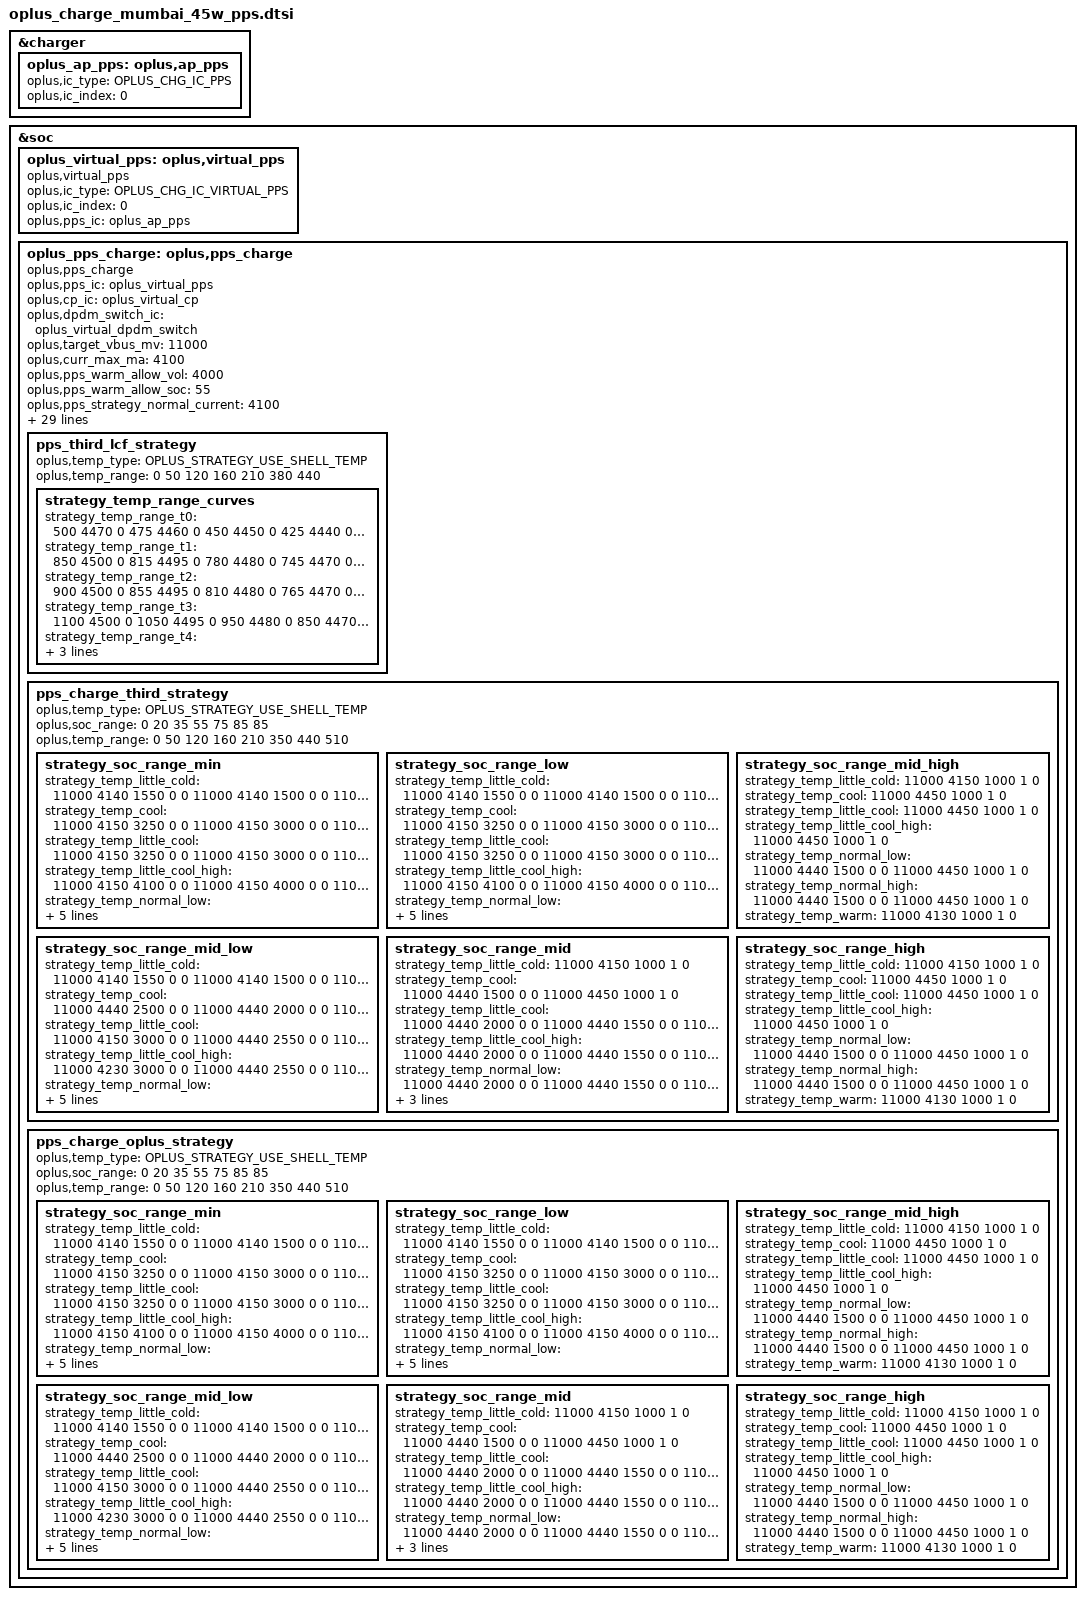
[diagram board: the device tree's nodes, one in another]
//ifdef OPLUS_FEATURE_CHG_BASIC

&charger {
	oplus_ap_pps: oplus,ap_pps {
		oplus,ic_type = <OPLUS_CHG_IC_PPS>;
		oplus,ic_index = <0>;
	};
};

&soc {
	oplus_virtual_pps: oplus,virtual_pps {
		compatible = "oplus,virtual_pps";

		oplus,ic_type = <OPLUS_CHG_IC_VIRTUAL_PPS>;
		oplus,ic_index = <0>;
		oplus,pps_ic = <&oplus_ap_pps>;
	};
	oplus_pps_charge: oplus,pps_charge {
		compatible = "oplus,pps_charge";
		oplus,pps_ic = <&oplus_virtual_pps>;
		oplus,cp_ic = <&oplus_virtual_cp>;
		oplus,dpdm_switch_ic = <&oplus_virtual_dpdm_switch>;

		// oplus,impedance_unit = <&oplus_pps_impedance_unit>;

		oplus,target_vbus_mv = <11000>;
		oplus,curr_max_ma = <4100>;

		oplus,pps_warm_allow_vol = <4000>;
		oplus,pps_warm_allow_soc = <55>;
		oplus,pps_strategy_normal_current = <4100>;
		oplus,pps_over_high_or_low_current = <4100>;
		oplus,pps_timeout_third = <17562>;
		oplus,pps_timeout_oplus = <17562>;
		oplus,pps_ibat_over_third = <9600>;
		oplus,pps_ibat_over_oplus = <9600>;
		oplus,pps_full_cool_sw_vbat = <4450>;
		oplus,pps_full_normal_sw_vbat = <4450>;
		oplus,pps_full_normal_hw_vbat = <4460>;
		oplus,pps_full_ffc_vbat = <4485>;
		oplus,pps_full_warm_vbat = <4130>;
		oplus,pps_full_cool_sw_vbat_third = <4450>;
		oplus,pps_full_normal_sw_vbat_third= <4450>;
		oplus,pps_full_normal_hw_vbat_third = <4460>;
		oplus,pps_current_change_timeout = <100>;
        // V1
		// oplus,pps_r_default = <270 45 10 45 20 20 20>;
		// oplus,pps_rmos_mohm = <5>;
		// oplus,pps_r_limit = <150 100 80 70 30>;
		oplus,pps_little_cool_high_temp = <210>;
		oplus,curve_strategy_name = "pps_ufcs_curve_v2";
		oplus,pps_strategy_batt_high_temp = <400 420 430
                                             400 410 420>;
		oplus,pps_strategy_high_current = <3000 2000 2000
                                           3000 3000 2000>;
		oplus,pps_charge_strategy_soc = <0 20 35 55 75 85 90>;
		oplus,pps_charge_strategy_temp = <0 50 120 160 350 440 510>;
		oplus,pps_low_curr_full_strategy_temp = <0 200 350 440>;
		oplus,pps_low_temp = <50>;

 		oplus,plc_strategy-data = <&pps_simple_strategy>;
 		oplus,plc_strategy-names = "default";
		pps_third_lcf_strategy {
			oplus,temp_type = <OPLUS_STRATEGY_USE_SHELL_TEMP>;
			oplus,temp_range = <0 50 120 160 210 380 440>;

			strategy_temp_range_curves {
				strategy_temp_range_t0 = <500 4470 0
								 475 4460 0
								 450 4450 0
								 425 4440 0
								 400 4430 1>;
				strategy_temp_range_t1 = <850 4500 0
								 815 4495 0
								 780 4480 0
								 745 4470 0
								 710 4460 1>;
				strategy_temp_range_t2 = <900 4500 0
								 855 4495 0
								 810 4480 0
								 765 4470 0
								 720 4460 1>;
				strategy_temp_range_t3 = <1100 4500 0
								 1050 4495 0
								 950 4480 0
								 850 4470 0
								 700 4460 1>;
				strategy_temp_range_t4 = <1150 4500 0
								 1100 4495 0
								 1000 4480 0
								 900 4470 0
								 750 4460 1>;
				strategy_temp_range_t5 = <1150 4500 0
								 1100 4495 0
								 1000 4480 0
								 900 4470 0
								 750 4460 1>;
			};
		};

		pps_charge_third_strategy {
			oplus,temp_type = <OPLUS_STRATEGY_USE_SHELL_TEMP>;
			oplus,soc_range = <0 20 35 55 75 85 85>;
			oplus,temp_range = <0 50 120 160 210 350 440 510>;

			strategy_soc_range_min {	//0-20
				strategy_temp_little_cold =	<11000 4140 1550 0 0
								11000 4140 1500 0 0
								11000 4150 1000 1 0>;
				strategy_temp_cool = <11000 4150 3250 0 0
								11000 4150 3000 0 0
								11000 4440 2550 0 0
								11000 4440 2500 0 0
								11000 4440 2000 0 0
								11000 4440 1550 0 0
								11000 4440 1500 0 0
								11000 4450 1000 1 0>;
				strategy_temp_little_cool =	<11000 4150 3250 0 0
								11000 4150 3000 0 0
								11000 4440 2550 0 0
								11000 4440 2500 0 0
								11000 4440 2000 0 0
								11000 4440 1550 0 0
								11000 4440 1500 0 0
								11000 4450 1000 1 0>;
				strategy_temp_little_cool_high = <11000 4150 4100 0 0
								11000 4150 4000 0 0
								11000 4150 3500 0 0
								11000 4230 3250 0 0
								11000 4230 3000 0 0
								11000 4440 2550 0 0
								11000 4440 2500 0 0
								11000 4440 2000 0 0
								11000 4440 1550 0 0
								11000 4440 1500 0 0
								11000 4450 1000 1 0>;
				strategy_temp_normal_low =	<11000 4150 4100 0 0
								11000 4150 4000 0 0
								11000 4150 3500 0 0
								11000 4230 3250 0 0
								11000 4230 3000 0 0
								11000 4440 2550 0 0
								11000 4440 2500 0 0
								11000 4440 2000 0 0
								11000 4440 1550 0 0
								11000 4440 1500 0 0
								11000 4450 1000 1 0>;
				strategy_temp_normal_high =	<11000 4150 4100 0 0
								11000 4150 4000 0 0
								11000 4150 3500 0 0
								11000 4230 3250 0 0
								11000 4230 3000 0 0
								11000 4440 2550 0 0
								11000 4440 2500 0 0
								11000 4440 2000 0 0
								11000 4440 1550 0 0
								11000 4440 1500 0 0
								11000 4450 1000 1 0>;
				strategy_temp_warm = <11000 4120 1850 0 0
								11000 4120 1500 0 0
								11000 4130 1000 1 0>;
			};
			strategy_soc_range_low {	//21-35
				strategy_temp_little_cold =	<11000 4140 1550 0 0
								11000 4140 1500 0 0
								11000 4150 1000 1 0>;
				strategy_temp_cool = <11000 4150 3250 0 0
								11000 4150 3000 0 0
								11000 4440 2550 0 0
								11000 4440 2500 0 0
								11000 4440 2000 0 0
								11000 4440 1550 0 0
								11000 4440 1500 0 0
								11000 4450 1000 1 0>;
				strategy_temp_little_cool =	<11000 4150 3250 0 0
								11000 4150 3000 0 0
								11000 4440 2550 0 0
								11000 4440 2500 0 0
								11000 4440 2000 0 0
								11000 4440 1550 0 0
								11000 4440 1500 0 0
								11000 4450 1000 1 0>;
				strategy_temp_little_cool_high = <11000 4150 4100 0 0
								11000 4150 4000 0 0
								11000 4150 3500 0 0
								11000 4230 3250 0 0
								11000 4230 3000 0 0
								11000 4440 2550 0 0
								11000 4440 2500 0 0
								11000 4440 2000 0 0
								11000 4440 1550 0 0
								11000 4440 1500 0 0
								11000 4450 1000 1 0>;
				strategy_temp_normal_low =	<11000 4150 4100 0 0
								11000 4150 4000 0 0
								11000 4150 3500 0 0
								11000 4230 3250 0 0
								11000 4230 3000 0 0
								11000 4440 2550 0 0
								11000 4440 2500 0 0
								11000 4440 2000 0 0
								11000 4440 1550 0 0
								11000 4440 1500 0 0
								11000 4450 1000 1 0>;
				strategy_temp_normal_high =	<11000 4150 4100 0 0
								11000 4150 4000 0 0
								11000 4150 3500 0 0
								11000 4230 3250 0 0
								11000 4230 3000 0 0
								11000 4440 2550 0 0
								11000 4440 2500 0 0
								11000 4440 2000 0 0
								11000 4440 1550 0 0
								11000 4440 1500 0 0
								11000 4450 1000 1 0>;
				strategy_temp_warm = <11000 4120 1850 0 0
								11000 4120 1500 0 0
								11000 4130 1000 1 0>;
			};
			strategy_soc_range_mid_low {	//36-55
				strategy_temp_little_cold =	<11000 4140 1550 0 0
								11000 4140 1500 0 0
								11000 4150 1000 1 0>;
				strategy_temp_cool = <11000 4440 2500 0 0
								11000 4440 2000 0 0
								11000 4440 1550 0 0
								11000 4440 1500 0 0
								11000 4450 1000 1 0>;
				strategy_temp_little_cool =	<11000 4150 3000 0 0
								11000 4440 2550 0 0
								11000 4440 2500 0 0
								11000 4440 2000 0 0
								11000 4440 1550 0 0
								11000 4440 1500 0 0
								11000 4450 1000 1 0>;
				strategy_temp_little_cool_high = <11000 4230 3000 0 0
								11000 4440 2550 0 0
								11000 4440 2500 0 0
								11000 4440 2000 0 0
								11000 4440 1550 0 0
								11000 4440 1500 0 0
								11000 4450 1000 1 0>;
				strategy_temp_normal_low =	<11000 4150 4100 0 0
								11000 4150 4000 0 0
								11000 4150 3500 0 0
								11000 4230 3250 0 0
								11000 4230 3000 0 0
								11000 4440 2550 0 0
								11000 4440 2500 0 0
								11000 4440 2000 0 0
								11000 4440 1550 0 0
								11000 4440 1500 0 0
								11000 4450 1000 1 0>;
				strategy_temp_normal_high =	<11000 4150 4100 0 0
								11000 4150 4000 0 0
								11000 4150 3500 0 0
								11000 4230 3250 0 0
								11000 4230 3000 0 0
								11000 4440 2550 0 0
								11000 4440 2500 0 0
								11000 4440 2000 0 0
								11000 4440 1550 0 0
								11000 4440 1500 0 0
								11000 4450 1000 1 0>;
				strategy_temp_warm = <11000 4120 1850 0 0
								11000 4120 1500 0 0
								11000 4130 1000 1 0>;
			};
			strategy_soc_range_mid {//56-75
				strategy_temp_little_cold =	<11000 4150 1000 1 0>;
				strategy_temp_cool = <11000 4440 1500 0 0
								11000 4450 1000 1 0>;
				strategy_temp_little_cool =	<11000 4440 2000 0 0
								11000 4440 1550 0 0
								11000 4440 1500 0 0
								11000 4450 1000 1 0>;
				strategy_temp_little_cool_high = <11000 4440 2000 0 0
								11000 4440 1550 0 0
								11000 4440 1500 0 0
								11000 4450 1000 1 0>;
				strategy_temp_normal_low = <11000 4440 2000 0 0
								11000 4440 1550 0 0
								11000 4440 1500 0 0
								11000 4450 1000 1 0>;
				strategy_temp_normal_high =	<11000 4440 2000 0 0
								11000 4440 1550 0 0
								11000 4440 1500 0 0
								11000 4450 1000 1 0>;
				strategy_temp_warm = <11000 4130 1000 1 0>;
			};
			strategy_soc_range_mid_high {//76-85
				strategy_temp_little_cold =	<11000 4150 1000 1 0>;
				strategy_temp_cool = <11000 4450 1000 1 0>;
				strategy_temp_little_cool =	<11000 4450 1000 1 0>;
				strategy_temp_little_cool_high = <11000 4450 1000 1 0>;
				strategy_temp_normal_low = <11000 4440 1500 0 0
								11000 4450 1000 1 0>;
				strategy_temp_normal_high =	<11000 4440 1500 0 0
								11000 4450 1000 1 0>;
				strategy_temp_warm = <11000 4130 1000 1 0>;
			};
			strategy_soc_range_high {//86-90
				strategy_temp_little_cold =	<11000 4150 1000 1 0>;
				strategy_temp_cool = <11000 4450 1000 1 0>;
				strategy_temp_little_cool =	<11000 4450 1000 1 0>;
				strategy_temp_little_cool_high = <11000 4450 1000 1 0>;
				strategy_temp_normal_low = <11000 4440 1500 0 0
								11000 4450 1000 1 0>;
				strategy_temp_normal_high =	<11000 4440 1500 0 0
								11000 4450 1000 1 0>;
				strategy_temp_warm = <11000 4130 1000 1 0>;
			};
		};

		pps_charge_oplus_strategy {
			oplus,temp_type = <OPLUS_STRATEGY_USE_SHELL_TEMP>;
			oplus,soc_range = <0 20 35 55 75 85 85>;
			oplus,temp_range = <0 50 120 160 210 350 440 510>;

						strategy_soc_range_min {	//0-20
				strategy_temp_little_cold =	<11000 4140 1550 0 0
								11000 4140 1500 0 0
								11000 4150 1000 1 0>;
				strategy_temp_cool = <11000 4150 3250 0 0
								11000 4150 3000 0 0
								11000 4440 2550 0 0
								11000 4440 2500 0 0
								11000 4440 2000 0 0
								11000 4440 1550 0 0
								11000 4440 1500 0 0
								11000 4450 1000 1 0>;
				strategy_temp_little_cool =	<11000 4150 3250 0 0
								11000 4150 3000 0 0
								11000 4440 2550 0 0
								11000 4440 2500 0 0
								11000 4440 2000 0 0
								11000 4440 1550 0 0
								11000 4440 1500 0 0
								11000 4450 1000 1 0>;
				strategy_temp_little_cool_high = <11000 4150 4100 0 0
								11000 4150 4000 0 0
								11000 4150 3500 0 0
								11000 4230 3250 0 0
								11000 4230 3000 0 0
								11000 4440 2550 0 0
								11000 4440 2500 0 0
								11000 4440 2000 0 0
								11000 4440 1550 0 0
								11000 4440 1500 0 0
								11000 4450 1000 1 0>;
				strategy_temp_normal_low =	<11000 4150 4100 0 0
								11000 4150 4000 0 0
								11000 4150 3500 0 0
								11000 4230 3250 0 0
								11000 4230 3000 0 0
								11000 4440 2550 0 0
								11000 4440 2500 0 0
								11000 4440 2000 0 0
								11000 4440 1550 0 0
								11000 4440 1500 0 0
								11000 4450 1000 1 0>;
				strategy_temp_normal_high =	<11000 4150 4100 0 0
								11000 4150 4000 0 0
								11000 4150 3500 0 0
								11000 4230 3250 0 0
								11000 4230 3000 0 0
								11000 4440 2550 0 0
								11000 4440 2500 0 0
								11000 4440 2000 0 0
								11000 4440 1550 0 0
								11000 4440 1500 0 0
								11000 4450 1000 1 0>;
				strategy_temp_warm = <11000 4120 1850 0 0
								11000 4120 1500 0 0
								11000 4130 1000 1 0>;
			};
			strategy_soc_range_low {	//21-35
				strategy_temp_little_cold =	<11000 4140 1550 0 0
								11000 4140 1500 0 0
								11000 4150 1000 1 0>;
				strategy_temp_cool = <11000 4150 3250 0 0
								11000 4150 3000 0 0
								11000 4440 2550 0 0
								11000 4440 2500 0 0
								11000 4440 2000 0 0
								11000 4440 1550 0 0
								11000 4440 1500 0 0
								11000 4450 1000 1 0>;
				strategy_temp_little_cool =	<11000 4150 3250 0 0
								11000 4150 3000 0 0
								11000 4440 2550 0 0
								11000 4440 2500 0 0
								11000 4440 2000 0 0
								11000 4440 1550 0 0
								11000 4440 1500 0 0
								11000 4450 1000 1 0>;
				strategy_temp_little_cool_high = <11000 4150 4100 0 0
								11000 4150 4000 0 0
								11000 4150 3500 0 0
								11000 4230 3250 0 0
								11000 4230 3000 0 0
								11000 4440 2550 0 0
								11000 4440 2500 0 0
								11000 4440 2000 0 0
								11000 4440 1550 0 0
								11000 4440 1500 0 0
								11000 4450 1000 1 0>;
				strategy_temp_normal_low =	<11000 4150 4100 0 0
								11000 4150 4000 0 0
								11000 4150 3500 0 0
								11000 4230 3250 0 0
								11000 4230 3000 0 0
								11000 4440 2550 0 0
								11000 4440 2500 0 0
								11000 4440 2000 0 0
								11000 4440 1550 0 0
								11000 4440 1500 0 0
								11000 4450 1000 1 0>;
				strategy_temp_normal_high =	<11000 4150 4100 0 0
								11000 4150 4000 0 0
								11000 4150 3500 0 0
								11000 4230 3250 0 0
								11000 4230 3000 0 0
								11000 4440 2550 0 0
								11000 4440 2500 0 0
								11000 4440 2000 0 0
								11000 4440 1550 0 0
								11000 4440 1500 0 0
								11000 4450 1000 1 0>;
				strategy_temp_warm = <11000 4120 1850 0 0
								11000 4120 1500 0 0
								11000 4130 1000 1 0>;
			};
			strategy_soc_range_mid_low {	//36-55
				strategy_temp_little_cold =	<11000 4140 1550 0 0
								11000 4140 1500 0 0
								11000 4150 1000 1 0>;
				strategy_temp_cool = <11000 4440 2500 0 0
								11000 4440 2000 0 0
								11000 4440 1550 0 0
								11000 4440 1500 0 0
								11000 4450 1000 1 0>;
				strategy_temp_little_cool =	<11000 4150 3000 0 0
								11000 4440 2550 0 0
								11000 4440 2500 0 0
								11000 4440 2000 0 0
								11000 4440 1550 0 0
								11000 4440 1500 0 0
								11000 4450 1000 1 0>;
				strategy_temp_little_cool_high = <11000 4230 3000 0 0
								11000 4440 2550 0 0
								11000 4440 2500 0 0
								11000 4440 2000 0 0
								11000 4440 1550 0 0
								11000 4440 1500 0 0
								11000 4450 1000 1 0>;
				strategy_temp_normal_low =	<11000 4150 4100 0 0
								11000 4150 4000 0 0
								11000 4150 3500 0 0
								11000 4230 3250 0 0
								11000 4230 3000 0 0
								11000 4440 2550 0 0
								11000 4440 2500 0 0
								11000 4440 2000 0 0
								11000 4440 1550 0 0
								11000 4440 1500 0 0
								11000 4450 1000 1 0>;
				strategy_temp_normal_high =	<11000 4150 4100 0 0
								11000 4150 4000 0 0
								11000 4150 3500 0 0
								11000 4230 3250 0 0
								11000 4230 3000 0 0
								11000 4440 2550 0 0
								11000 4440 2500 0 0
								11000 4440 2000 0 0
								11000 4440 1550 0 0
								11000 4440 1500 0 0
								11000 4450 1000 1 0>;
				strategy_temp_warm = <11000 4120 1850 0 0
								11000 4120 1500 0 0
								11000 4130 1000 1 0>;
			};
			strategy_soc_range_mid {//56-75
				strategy_temp_little_cold =	<11000 4150 1000 1 0>;
				strategy_temp_cool = <11000 4440 1500 0 0
								11000 4450 1000 1 0>;
				strategy_temp_little_cool =	<11000 4440 2000 0 0
								11000 4440 1550 0 0
								11000 4440 1500 0 0
								11000 4450 1000 1 0>;
				strategy_temp_little_cool_high = <11000 4440 2000 0 0
								11000 4440 1550 0 0
								11000 4440 1500 0 0
								11000 4450 1000 1 0>;
				strategy_temp_normal_low = <11000 4440 2000 0 0
								11000 4440 1550 0 0
								11000 4440 1500 0 0
								11000 4450 1000 1 0>;
				strategy_temp_normal_high =	<11000 4440 2000 0 0
								11000 4440 1550 0 0
								11000 4440 1500 0 0
								11000 4450 1000 1 0>;
				strategy_temp_warm = <11000 4130 1000 1 0>;
			};
			strategy_soc_range_mid_high {//76-85
				strategy_temp_little_cold =	<11000 4150 1000 1 0>;
				strategy_temp_cool = <11000 4450 1000 1 0>;
				strategy_temp_little_cool =	<11000 4450 1000 1 0>;
				strategy_temp_little_cool_high = <11000 4450 1000 1 0>;
				strategy_temp_normal_low = <11000 4440 1500 0 0
								11000 4450 1000 1 0>;
				strategy_temp_normal_high =	<11000 4440 1500 0 0
								11000 4450 1000 1 0>;
				strategy_temp_warm = <11000 4130 1000 1 0>;
			};
			strategy_soc_range_high {//86-90
				strategy_temp_little_cold =	<11000 4150 1000 1 0>;
				strategy_temp_cool = <11000 4450 1000 1 0>;
				strategy_temp_little_cool =	<11000 4450 1000 1 0>;
				strategy_temp_little_cool_high = <11000 4450 1000 1 0>;
				strategy_temp_normal_low = <11000 4440 1500 0 0
								11000 4450 1000 1 0>;
				strategy_temp_normal_high =	<11000 4440 1500 0 0
								11000 4450 1000 1 0>;
				strategy_temp_warm = <11000 4130 1000 1 0>;
			};
		};
	};
};
//#endif OPLUS_FEATURE_CHG_BASIC
